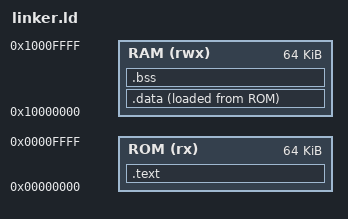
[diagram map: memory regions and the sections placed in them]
OUTPUT_ARCH(riscv)
ENTRY(_start)

MEMORY
{
  ROM (rx)  : ORIGIN = 0x00000000, LENGTH = 64K
  RAM (rwx) : ORIGIN = 0x10000000, LENGTH = 64K
}

SECTIONS
{
  .text : {
    KEEP(*(.init))
    *(.text*)
    *(.rodata*)
  } > ROM

  _sidata = LOADADDR(.data);
  .data : {
    _sdata = .;
    *(.data*)
    _edata = .;
  } > RAM AT > ROM

  .bss (NOLOAD) : {
    _sbss = .;
    *(.bss*)
    *(COMMON)
    _ebss = .;
  } > RAM

  . = ALIGN(16);
  _stack_top = ORIGIN(RAM) + LENGTH(RAM);
}
